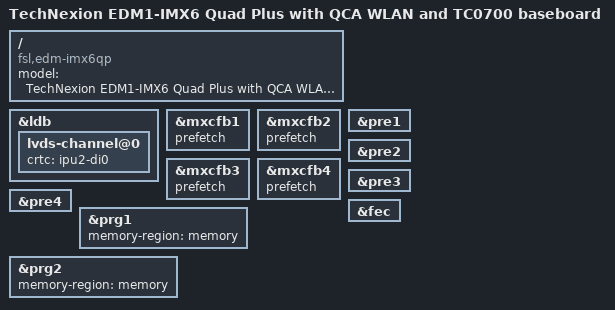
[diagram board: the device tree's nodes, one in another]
/*
 * Copyright 2018 TechNexion Ltd.
 *
 * Author: Wig Cheng <wig.cheng@technexion.com>
 *         Richard Hu <richard.hu@technexion.com>
 *         Tapani Utriainen <tapani@technexion.com>
 *         Ray Chang <ray.chang@technexion.com>
 *
 * This program is free software; you can redistribute it and/or modify
 * it under the terms of the GNU General Public License version 2 as
 * published by the Free Software Foundation.
 */

/dts-v1/;
#include <dt-bindings/interrupt-controller/irq.h>
#include "imx6qp.dtsi"
#include "imx6qdl-edm-qca.dtsi"
#include "baseboard_edm1_tc0700.dtsi"

/ {
	model = "TechNexion EDM1-IMX6 Quad Plus with QCA WLAN and TC0700 baseboard";
	compatible = "fsl,edm-imx6qp", "fsl,imx6qp";
};

&ldb {
	lvds-channel@0 {
		crtc = "ipu2-di0";
	};
};

&mxcfb1 {
	prefetch;
	status = "okay";
};

&mxcfb2 {
	prefetch;
	status = "okay";
};

&mxcfb3 {
	prefetch;
	status = "okay";
};

&mxcfb4 {
	prefetch;
	status = "okay";
};

&pre1 {
	status = "okay";
};

&pre2 {
	status = "okay";
};

&pre3 {
	status = "okay";
};

&pre4 {
	status = "okay";
};

&prg1 {
	memory-region = <&memory>;
	status = "okay";
};

&prg2 {
	memory-region = <&memory>;
	status = "okay";
};

&fec {
	/delete-property/ phy-reset-gpios;
};
